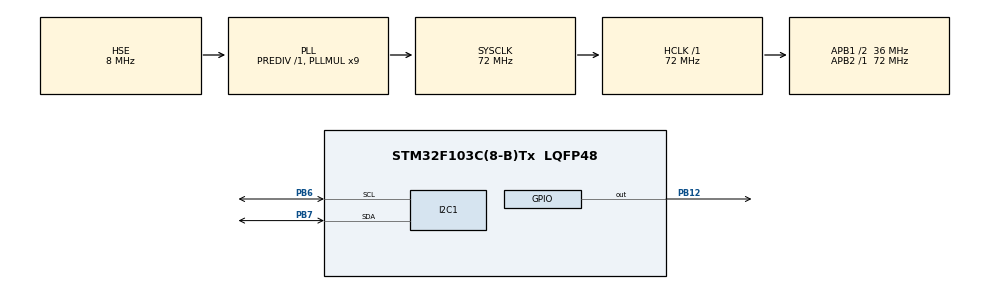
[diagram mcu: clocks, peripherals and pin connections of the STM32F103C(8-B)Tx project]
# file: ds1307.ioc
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Mcu.Family=STM32F1
Mcu.Name=STM32F103C(8-B)Tx
Mcu.Package=LQFP48
NVIC.I2C1_ER_IRQn=true\:1\:0\:true\:false\:true\:true\:true\:true
NVIC.I2C1_EV_IRQn=true\:1\:0\:true\:false\:true\:true\:true\:true
NVIC.PriorityGroup=NVIC_PRIORITYGROUP_4
PA13.Mode=Serial_Wire
PA13.Signal=SYS_JTMS-SWDIO
PA14.Mode=Serial_Wire
PA14.Signal=SYS_JTCK-SWCLK
PB12.Signal=GPIO_Output
PB6.Mode=I2C
PB6.Signal=I2C1_SCL
PB7.Mode=I2C
PB7.Signal=I2C1_SDA
PD0-OSC_IN.Mode=HSE-External-Oscillator
PD0-OSC_IN.Signal=RCC_OSC_IN
PD1-OSC_OUT.Mode=HSE-External-Oscillator
PD1-OSC_OUT.Signal=RCC_OSC_OUT
ProjectManager.HeapSize=0x200
ProjectManager.StackSize=0x400
ProjectManager.TargetToolchain=STM32CubeIDE
RCC.AHBFreq_Value=72000000
RCC.APB1CLKDivider=RCC_HCLK_DIV2
RCC.APB1Freq_Value=36000000
RCC.APB1TimFreq_Value=72000000
RCC.APB2Freq_Value=72000000
RCC.APB2TimFreq_Value=72000000
RCC.HCLKFreq_Value=72000000
RCC.PLLMUL=RCC_PLL_MUL9
RCC.PLLSourceVirtual=RCC_PLLSOURCE_HSE
RCC.SYSCLKFreq_VALUE=72000000
RCC.SYSCLKSource=RCC_SYSCLKSOURCE_PLLCLK
RCC.USBFreq_Value=72000000
board=custom

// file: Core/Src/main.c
/* USER CODE BEGIN Header */
/**
  ******************************************************************************
  * @file           : main.c
  * @brief          : Main program body
  ******************************************************************************
  * @attention
  *
  * Copyright (c) 2023 STMicroelectronics.
  * All rights reserved.
  *
  * This software is licensed under terms that can be found in the LICENSE file
  * in the root directory of this software component.
  * If no LICENSE file comes with this software, it is provided AS-IS.
  *
  ******************************************************************************
  */
/* USER CODE END Header */
#include "main.h"

/* USER CODE BEGIN PTD */
#define DS1307_ADDRESS (0x68<<1)
typedef struct {
	uint8_t sec;
	uint8_t min;
	uint8_t hour;
	uint8_t day;
	uint8_t date;
	uint8_t month;
	uint8_t year;
	uint8_t ap;
}DS1307_Struct;
DS1307_Struct ds1307;
/* USER CODE END PTD */

/* USER CODE BEGIN PD */
#define AM 0
#define PM 1
/* USER CODE END PD */

I2C_HandleTypeDef hi2c1;

void SystemClock_Config(void);
static void MX_GPIO_Init(void);
static void MX_I2C1_Init(void);
/* USER CODE BEGIN PFP */
uint8_t B2D (uint8_t num)// Chuyen tu binary sang decimal
{
	return ((num/16 * 10) + (num % 16));
}

uint8_t D2B (uint8_t num) // Chuyen tu decimal sang binary
{
	return ((num/10 * 16) + (num % 10));
}

void DS1307_getTime(int type)
{
	uint8_t buffer[7];
	HAL_I2C_Master_Transmit(&hi2c1, DS1307_ADDRESS, 0x00, 1, 1000);
	HAL_I2C_Master_Receive(&hi2c1, DS1307_ADDRESS, buffer, 7, 1000);
	/* Read time */
	ds1307.sec 		= B2D(buffer[0] & 0x7f);
	ds1307.min 		= B2D(buffer[1]);
	if(type == 12 ) {
		if(buffer[2] & (1<<5)) ds1307.ap = 'P';
		else ds1307.ap = 'A';
		uint8_t Mode_12Hr_10_Adder_Trigger = buffer[2] & (1 << 4);
		uint8_t Byte_Single_Digit_Hours = buffer[2];

		//  Code to set bits 4 - 7 to 0
		Byte_Single_Digit_Hours = Byte_Single_Digit_Hours & 0x0f;

		if(Mode_12Hr_10_Adder_Trigger == 0)
		{
			ds1307.hour 	= B2D(Byte_Single_Digit_Hours);
		}
		else	ds1307.hour = B2D(Byte_Single_Digit_Hours) + 10;
	}
	else {
		ds1307.hour 	= B2D(buffer[2] & 0x3f);
		ds1307.ap = 0;
	}
	ds1307.day 		= B2D(buffer[3]);
	ds1307.date 	= B2D(buffer[4]);
	ds1307.month 	= B2D(buffer[5]);
	ds1307.year 	= B2D(buffer[6]);
  }

void DS1307_setTime(uint8_t hour, uint8_t min, uint8_t sec, uint8_t day, uint8_t date, uint8_t month, uint8_t year)
{
	uint8_t buffer[8];
	buffer[0] = 0x00;
	buffer[1] = D2B(sec);
	buffer[2] = D2B(min);
	buffer[3] = D2B(hour);
	buffer[4] = D2B(day);
	buffer[5] = D2B(date);
	buffer[6] = D2B(month);
	buffer[7] = D2B(year);
	HAL_I2C_Master_Transmit(&hi2c1, DS1307_ADDRESS, buffer, 8, 1000);
}

void DS1307_setTime_12(uint8_t hour, uint8_t ap, uint8_t min, uint8_t sec, uint8_t day, uint8_t date, uint8_t month, uint8_t year)
{
	uint8_t buffer[8],h;
	buffer[0] = 0x00;
	buffer[1] = D2B(sec);
	buffer[2] = D2B(min);
	if(ap == PM)	buffer[3] = buffer[3] | (1 << 6) | (1 << 5);
	else buffer[3] = buffer[3] | (1 << 6);
	if(hour >= 10){
		buffer[3] = buffer[3] | (1 << 4);
		h = hour - 10;
	}
	else h = hour ;
	buffer[3] = buffer[3] | D2B(h);
	buffer[4] = D2B(day);
	buffer[5] = D2B(date);
	buffer[6] = D2B(month);
	buffer[7] = D2B(year);
	HAL_I2C_Master_Transmit(&hi2c1, DS1307_ADDRESS, buffer, 8, 1000);
}
/* USER CODE END PFP */

int main(void)
{

  /* MCU Configuration--------------------------------------------------------*/

  /* Reset of all peripherals, Initializes the Flash interface and the Systick. */
  HAL_Init();

  /* Configure the system clock */
  SystemClock_Config();

  /* Initialize all configured peripherals */
  MX_GPIO_Init();
  MX_I2C1_Init();
  /* USER CODE BEGIN 2 */
  //DS1307_setTime(12, 59, 50, 7, 31, 12, 23);
  DS1307_setTime_12(12, AM, 59, 50, 7, 31, 12, 23);
  //DS1307_setTime_12(hour,AM, min, sec, day, date, month, year);
  /* USER CODE END 2 */

  /* Infinite loop */
  while (1)
  {

    /* USER CODE BEGIN 3 */
	  DS1307_getTime(12);
	  //DS1307_getTime(24);
	  HAL_Delay(1000);
  }
  /* USER CODE END 3 */
}

void SystemClock_Config(void)
{
  RCC_OscInitTypeDef RCC_OscInitStruct = {0};
  RCC_ClkInitTypeDef RCC_ClkInitStruct = {0};

  /** Initializes the RCC Oscillators according to the specified parameters
  * in the RCC_OscInitTypeDef structure.
  */
  RCC_OscInitStruct.OscillatorType = RCC_OSCILLATORTYPE_HSE;
  RCC_OscInitStruct.HSEState = RCC_HSE_ON;
  RCC_OscInitStruct.HSEPredivValue = RCC_HSE_PREDIV_DIV1;
  RCC_OscInitStruct.HSIState = RCC_HSI_ON;
  RCC_OscInitStruct.PLL.PLLState = RCC_PLL_ON;
  RCC_OscInitStruct.PLL.PLLSource = RCC_PLLSOURCE_HSE;
  RCC_OscInitStruct.PLL.PLLMUL = RCC_PLL_MUL9;
  if (HAL_RCC_OscConfig(&RCC_OscInitStruct) != HAL_OK)
  {
    Error_Handler();
  }

  /** Initializes the CPU, AHB and APB buses clocks
  */
  RCC_ClkInitStruct.ClockType = RCC_CLOCKTYPE_HCLK|RCC_CLOCKTYPE_SYSCLK
                              |RCC_CLOCKTYPE_PCLK1|RCC_CLOCKTYPE_PCLK2;
  RCC_ClkInitStruct.SYSCLKSource = RCC_SYSCLKSOURCE_PLLCLK;
  RCC_ClkInitStruct.AHBCLKDivider = RCC_SYSCLK_DIV1;
  RCC_ClkInitStruct.APB1CLKDivider = RCC_HCLK_DIV2;
  RCC_ClkInitStruct.APB2CLKDivider = RCC_HCLK_DIV1;

  if (HAL_RCC_ClockConfig(&RCC_ClkInitStruct, FLASH_LATENCY_2) != HAL_OK)
  {
    Error_Handler();
  }
}

static void MX_I2C1_Init(void)
{

  hi2c1.Instance = I2C1;
  hi2c1.Init.ClockSpeed = 100000;
  hi2c1.Init.DutyCycle = I2C_DUTYCYCLE_2;
  hi2c1.Init.OwnAddress1 = 0;
  hi2c1.Init.AddressingMode = I2C_ADDRESSINGMODE_7BIT;
  hi2c1.Init.DualAddressMode = I2C_DUALADDRESS_DISABLE;
  hi2c1.Init.OwnAddress2 = 0;
  hi2c1.Init.GeneralCallMode = I2C_GENERALCALL_DISABLE;
  hi2c1.Init.NoStretchMode = I2C_NOSTRETCH_DISABLE;
  if (HAL_I2C_Init(&hi2c1) != HAL_OK)
  {
    Error_Handler();
  }

}

static void MX_GPIO_Init(void)
{
  GPIO_InitTypeDef GPIO_InitStruct = {0};

  /* GPIO Ports Clock Enable */
  __HAL_RCC_GPIOD_CLK_ENABLE();
  __HAL_RCC_GPIOB_CLK_ENABLE();
  __HAL_RCC_GPIOA_CLK_ENABLE();

  /*Configure GPIO pin Output Level */
  HAL_GPIO_WritePin(GPIOB, GPIO_PIN_12, GPIO_PIN_RESET);

  /*Configure GPIO pin : PB12 */
  GPIO_InitStruct.Pin = GPIO_PIN_12;
  GPIO_InitStruct.Mode = GPIO_MODE_OUTPUT_PP;
  GPIO_InitStruct.Pull = GPIO_NOPULL;
  GPIO_InitStruct.Speed = GPIO_SPEED_FREQ_LOW;
  HAL_GPIO_Init(GPIOB, &GPIO_InitStruct);

}

void Error_Handler(void)
{
  __disable_irq();
  while (1)
  {
  }
}
